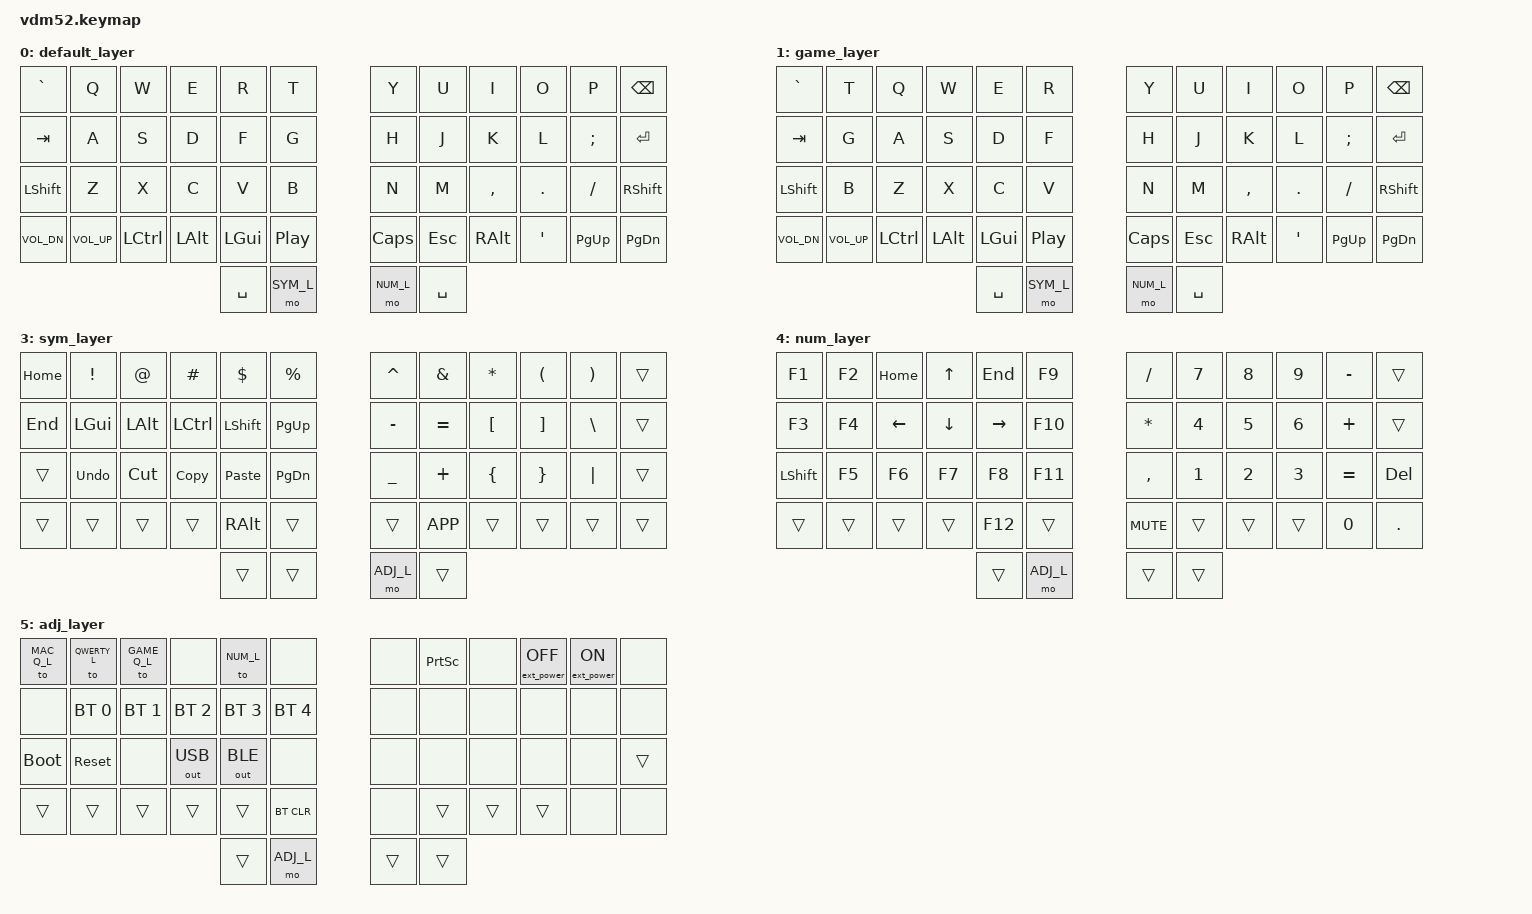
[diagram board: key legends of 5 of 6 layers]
#include <behaviors.dtsi>
#include <dt-bindings/zmk/bt.h>
#include <dt-bindings/zmk/ext_power.h>
#include <dt-bindings/zmk/keys.h>
#include <dt-bindings/zmk/outputs.h>

#define QWERTY_L 0
#define GAME_Q_L 1
#define MAC_Q_L  2
#define SYM_L    3
#define NUM_L    4
#define ADJ_L    5


#define Undo   LC(Z)
#define Cut    LC(X)
#define Copy   LC(C)
#define Paste  LC(V)

/ {
        keymap {
                compatible = "zmk,keymap";

                default_layer {
/* QWERTY
 * -------------------------------------------------------------------------------------------------------------------------------------
 * | `     |   Q   |   W   |   E   |   R   |   T   |-----------------------------------|   Y   |   U   |   I   |   O   |   P   | BKSPC |
 * | TAB   |   A   |   S   |   D   |   F   |   G   |-----------------------------------|   H   |   J   |   K   |   L   |   ;   | ENTER |
 * | SHIFT |   Z   |   X   |   C   |   V   |   B   |-----------------------------------|   N   |   M   |   ,   |   .   |   /   | SHIFT |
 * ----------------|  VOL- |  VOL+ |  CTRL |  ALT  |  GUI  | Play/P |--| CAPS  |  ESC  |  ALT  |   '   | PG_UP | PG_DN |----------------
 * ------------------------------------------------| SPACE |  Sym   |--|  Num  | SPACE |------------------------------------------------
 */
                        bindings = <
&kp  GRAVE    &kp  Q        &kp  W        &kp  E        &kp  R        &kp  T                                                                        &kp  Y        &kp  U        &kp  I        &kp  O        &kp  P        &kp  BSPC
&kp  TAB      &kp  A        &kp  S        &kp  D        &kp  F        &kp  G                                                                        &kp  H        &kp  J        &kp  K        &kp  L        &kp  SEMI     &kp  ENTER  
&kp  LSHFT    &kp  Z        &kp  X        &kp  C        &kp  V        &kp  B                                                                        &kp  N        &kp  M        &kp  COMMA    &kp  DOT      &kp  SLASH    &kp  RSHFT
                            &kp  C_VOL_DN &kp  C_VOL_UP &kp  LCTRL    &kp  LALT     &kp  LGUI     &kp  C_PP          &kp  CAPS        &kp  ESC      &kp  RALT     &kp  SQT      &kp  PG_UP    &kp  PG_DN
                                                                                    &kp  SPACE    &mo  SYM_L         &mo  NUM_L       &kp  SPACE
                        >;

                };

                game_layer {
/* QWERTY
 * -------------------------------------------------------------------------------------------------------------------------------------
 * | `     |   T   |   Q   |   W   |   E   |   R   |-----------------------------------|   Y   |   U   |   I   |   O   |   P   | BKSPC |
 * | TAB   |   G   |   A   |   S   |   D   |   F   |-----------------------------------|   H   |   J   |   K   |   L   |   ;   | ENTER |
 * | SHIFT |   B   |   Z   |   X   |   C   |   V   |-----------------------------------|   N   |   M   |   ,   |   .   |   /   | SHIFT |
 * ----------------|  VOL- |  VOL+ |  CTRL |  ALT  |  GUI  | Play/P |--| CAPS  |  ESC  |  ALT  |   '   | PG_UP | PG_DN |----------------
 * ------------------------------------------------| SPACE |  Sym   |--|  Num  | SPACE |------------------------------------------------
 */
                        bindings = <
&kp  GRAVE    &kp  T        &kp  Q        &kp  W        &kp  E        &kp  R                                                                        &kp  Y        &kp  U        &kp  I        &kp  O        &kp  P        &kp  BSPC
&kp  TAB      &kp  G        &kp  A        &kp  S        &kp  D        &kp  F                                                                        &kp  H        &kp  J        &kp  K        &kp  L        &kp  SEMI     &kp  ENTER  
&kp  LSHFT    &kp  B        &kp  Z        &kp  X        &kp  C        &kp  V                                                                        &kp  N        &kp  M        &kp  COMMA    &kp  DOT      &kp  SLASH    &kp  RSHFT
                            &kp  C_VOL_DN &kp  C_VOL_UP &kp  LCTRL    &kp  LALT     &kp  LGUI     &kp  C_PP          &kp  CAPS        &kp  ESC      &kp  RALT     &kp  SQT      &kp  PG_UP    &kp  PG_DN
                                                                                    &kp  SPACE    &mo  SYM_L         &mo  NUM_L       &kp  SPACE
                        >;

                };

                mac_default_layer {
/* MAC_QWERTY
 * -------------------------------------------------------------------------------------------------------------------------------------
 * | `     |   Q   |   W   |   E   |   R   |   T   |-----------------------------------|   Y   |   U   |   I   |   O   |   P   | BKSPC |
 * | TAB   |   A   |   S   |   D   |   F   |   G   |-----------------------------------|   H   |   J   |   K   |   L   |   ;   | ENTER |
 * | SHIFT |   Z   |   X   |   C   |   V   |   B   |-----------------------------------|   N   |   M   |   ,   |   .   |   /   | SHIFT |
 * ----------------|  VOL- |  VOL+ |  CTRL |   CMD |  ALT  | Play/P |--| CAPS  |  ESC  |  ALT  |   '   | PG_UP | PG_DN |----------------
 * ------------------------------------------------| SPACE |  Sym   |--|  Num  | SPACE |------------------------------------------------
 */
                        bindings = <
&kp  GRAVE    &kp  Q        &kp  W        &kp  E        &kp  R        &kp  T                                                                        &kp  Y        &kp  U        &kp  I        &kp  O        &kp  P        &kp  BSPC
&kp  TAB      &kp  A        &kp  S        &kp  D        &kp  F        &kp  G                                                                        &kp  H        &kp  J        &kp  K        &kp  L        &kp  SEMI     &kp  ENTER  
&kp  LSHFT    &kp  Z        &kp  X        &kp  C        &kp  V        &kp  B                                                                        &kp  N        &kp  M        &kp  COMMA    &kp  DOT      &kp  SLASH    &kp  RSHFT
                            &kp  &trans   &kp  &trans   &kp  LCTRL     &kp  LCMD    &kp  LALT     &kp  C_PP          &kp  CAPS        &kp  ESC      &kp  RALT     &kp  SQT      &kp  PG_UP    &kp  PG_DN
                                                                                    &kp  SPACE    &mo  SYM_L         &mo  NUM_L       &kp  SPACE
                        >;

                };

                sym_layer {
/* SYM
 * -------------------------------------------------------------------------------------------------------------------------------------
 * | HOME  |   !   |   @   |   #   |   $   |   %   |-----------------------------------|   ^   |   &   |   *   |   (   |   )   | BSPC  |
 * | END   |  GUI  |  Alt  | Ctrl  | Shift | Pg Up |-----------------------------------|   -   |   =   |   [   |   ]   |   \   | ENTER |
 * | Shift |  UnDo |  Cut  | Copy  | Paste | Pg Dn |-----------------------------------|   _   |   +   |   {   |   }   |   |   | SHIFT |
 * ----------------|       |       |       |       |OsAltGr|        |--|       | MENU  |       |       |       |       |----------------
 * ------------------------------------------------|       |        |--| ADJ_L |       |------------------------------------------------
 */
                        bindings = <
&kp  HOME     &kp  EXCL     &kp  AT       &kp  HASH     &kp  DOLLAR   &kp  PERCENT                                                                   &kp  CARET    &kp  AMPS     &kp  ASTRK    &kp  LPAR     &kp  RPAR     &trans
&kp  END      &kp  LGUI     &kp  LALT     &kp  LCTRL    &kp  LSHFT    &kp  PG_UP                                                                     &kp  MINUS    &kp  EQUAL    &kp  LBKT     &kp  RBKT     &kp  BSLH     &trans
&trans        &kp  Undo     &kp  Cut      &kp  Copy     &kp  Paste    &kp  PG_DN                                                                     &kp  UNDER    &kp  PLUS     &kp  LBRC     &kp  RBRC     &kp  PIPE     &trans
                            &trans        &trans        &trans        &trans        &kp  RALT     &trans              &trans           &kp  K_APP    &trans        &trans        &trans        &trans
                                                                                    &trans        &trans              &mo ADJ_L        &trans
                        >;

                };

                num_layer {
/* NUM
 * -------------------------------------------------------------------------------------------------------------------------------------
 * | F1    |  F2   | Home  |  Up   |  End  |  F9   |-----------------------------------|   /   |   7   |   8   |   9   |   -   | BSPC  |
 * | F3    |  F4   | Left  | Down  | Right |  F10  |-----------------------------------|   *   |   4   |   5   |   6   |   +   | ENTER |
 * | Shift |  F5   |  F6   |  F7   |  F8   |  F11  |-----------------------------------|   ,   |   1   |   2   |   3   |   =   | DELETE|
 * ----------------|       |       |       |       |  F12  |        |--| MUTE  |       |       |       |   0   |   .   |----------------
 * ------------------------------------------------|       |  ADJ_L |--|       |       |------------------------------------------------
 */
                        bindings = <
&kp  F1       &kp  F2       &kp  HOME     &kp  UP       &kp  END      &kp  F9                                                                        &kp  SLASH  &kp   N7      &kp   N8      &kp   N9      &kp  MINUS    &trans
&kp  F3       &kp  F4       &kp  LEFT     &kp  DOWN     &kp  RIGHT    &kp  F10                                                                       &kp  ASTRK  &kp   N4      &kp   N5      &kp   N6      &kp  PLUS     &trans
&kp  LSHFT    &kp  F5       &kp  F6       &kp  F7       &kp  F8       &kp  F11                                                                       &kp  COMMA  &kp   N1      &kp   N2      &kp   N3      &kp  EQUAL    &kp DEL
                            &trans        &trans        &trans        &trans        &kp F12       &trans                 &kp C_MUTE    &trans        &trans      &trans        &kp   N0      &kp   DOT
                                                                                    &trans        &mo ADJ_L              &trans        &trans
                        >;

                };

                adj_layer {
/* ADJUST
 * ----------------------------------------------------------------------------------------------------------------------------------------
 * |MAC_QWERTY| QWERTY| GAME_L|       | NUM   |       |-----------------------------------|       |Prt Scr|       | EP_OFF| EP_ON |       |
 * |          | BT 0  | BT 1  | BT 2  | BT 3  | BT 4  |-----------------------------------|       |       |       |       |       |       |
 * |   BOOTL  | RESET |       |OUT_USB|OUT_BLE|       |-----------------------------------|       |       |       |       |       | SHIFT |
 * -------------------|       |       |       |       |       | BT_CLR |--|       |       |       |       |       |       |----------------
 * ---------------------------------------------------|       |        |--|       |       |------------------------------------------------
 */
                        bindings = <
&to MAC_Q_L   &to  QWERTY_L &to  GAME_Q_L &none         &to  NUM_L    &none                                                                             &none             &kp PRINTSCREEN    &none         &ext_power EP_OFF  &ext_power EP_ON &none
&none         &bt  BT_SEL 0 &bt  BT_SEL 1 &bt  BT_SEL 2 &bt  BT_SEL 3 &bt  BT_SEL 4                                                                     &none             &none              &none            &none           &none            &none
&bootloader   &sys_reset    &none         &out OUT_USB  &out OUT_BLE  &none                                                                             &none             &none              &none            &none           &none            &trans
                            &trans        &trans        &trans        &trans        &trans        &bt BT_CLR             &none         &trans           &trans            &trans             &none            &none
                                                                                    &trans        &mo ADJ_L              &trans        &trans
                        >;

                };
        };
};
